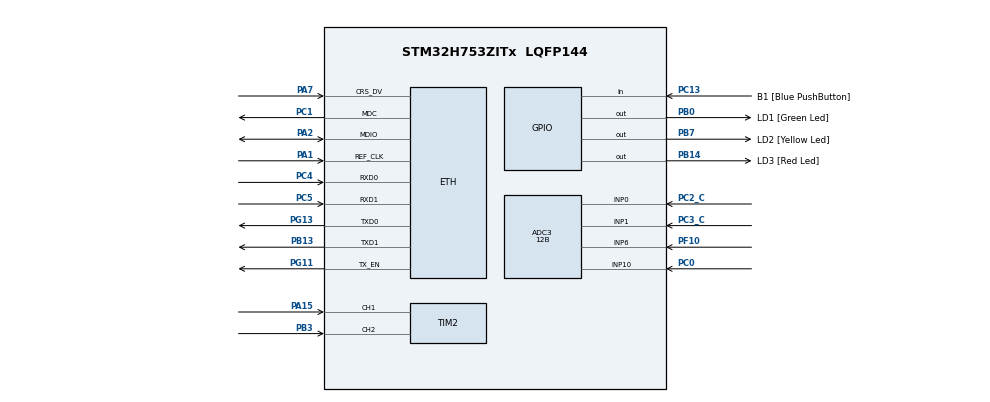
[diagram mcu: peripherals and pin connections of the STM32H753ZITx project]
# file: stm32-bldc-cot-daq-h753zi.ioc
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ADC3.Channel-1\#ChannelRegularConversion=ADC_CHANNEL_10
ADC3.Channel-2\#ChannelRegularConversion=ADC_CHANNEL_1
ADC3.Channel-3\#ChannelRegularConversion=ADC_CHANNEL_0
ADC3.Channel-4\#ChannelRegularConversion=ADC_CHANNEL_6
ADC3.ClockPrescaler=ADC_CLOCK_ASYNC_DIV2
ADC3.ConversionDataManagement=ADC_CONVERSIONDATA_DMA_CIRCULAR
ADC3.EOCSelection=ADC_EOC_SEQ_CONV
ADC3.ExternalTrigConv=ADC_EXTERNALTRIG_T3_TRGO
ADC3.NbrOfConversion=4
ADC3.NbrOfConversionFlag=1
ADC3.OffsetNumber-1\#ChannelRegularConversion=ADC_OFFSET_NONE
ADC3.OffsetNumber-2\#ChannelRegularConversion=ADC_OFFSET_NONE
ADC3.OffsetNumber-3\#ChannelRegularConversion=ADC_OFFSET_NONE
ADC3.OffsetNumber-4\#ChannelRegularConversion=ADC_OFFSET_NONE
ADC3.OffsetSignedSaturation-1\#ChannelRegularConversion=DISABLE
ADC3.OffsetSignedSaturation-2\#ChannelRegularConversion=DISABLE
ADC3.OffsetSignedSaturation-3\#ChannelRegularConversion=DISABLE
ADC3.OffsetSignedSaturation-4\#ChannelRegularConversion=DISABLE
ADC3.Rank-1\#ChannelRegularConversion=1
ADC3.Rank-2\#ChannelRegularConversion=2
ADC3.Rank-3\#ChannelRegularConversion=3
ADC3.Rank-4\#ChannelRegularConversion=4
ADC3.Resolution=ADC_RESOLUTION_12B
ADC3.SamplingTime-1\#ChannelRegularConversion=ADC_SAMPLETIME_16CYCLES_5
ADC3.SamplingTime-2\#ChannelRegularConversion=ADC_SAMPLETIME_16CYCLES_5
ADC3.SamplingTime-3\#ChannelRegularConversion=ADC_SAMPLETIME_16CYCLES_5
ADC3.SamplingTime-4\#ChannelRegularConversion=ADC_SAMPLETIME_16CYCLES_5
Bdma.ADC3.0.Direction=DMA_PERIPH_TO_MEMORY
Bdma.ADC3.0.EventEnable=DISABLE
Bdma.ADC3.0.Instance=BDMA_Channel0
Bdma.ADC3.0.MemDataAlignment=DMA_MDATAALIGN_HALFWORD
Bdma.ADC3.0.MemInc=DMA_MINC_ENABLE
Bdma.ADC3.0.Mode=DMA_CIRCULAR
Bdma.ADC3.0.PeriphDataAlignment=DMA_PDATAALIGN_HALFWORD
Bdma.ADC3.0.PeriphInc=DMA_PINC_DISABLE
Bdma.ADC3.0.Polarity=HAL_DMAMUX_REQ_GEN_RISING
Bdma.ADC3.0.Priority=DMA_PRIORITY_LOW
Bdma.ADC3.0.RequestNumber=1
Bdma.ADC3.0.SignalID=NONE
Bdma.ADC3.0.SyncEnable=DISABLE
Bdma.ADC3.0.SyncPolarity=HAL_DMAMUX_SYNC_NO_EVENT
Bdma.ADC3.0.SyncRequestNumber=1
Bdma.ADC3.0.SyncSignalID=NONE
Bdma.Request0=ADC3
Bdma.RequestsNb=1
CORTEX_M7.AccessPermission-Cortex_Memory_Protection_Unit_Region0_Settings=MPU_REGION_FULL_ACCESS
CORTEX_M7.BaseAddress-Cortex_Memory_Protection_Unit_Region0_Settings=0x30000000
CORTEX_M7.CPU_DCache=Enabled
CORTEX_M7.CPU_ICache=Enabled
CORTEX_M7.DisableExec-Cortex_Memory_Protection_Unit_Region0_Settings=MPU_INSTRUCTION_ACCESS_DISABLE
CORTEX_M7.Enable-Cortex_Memory_Protection_Unit_Region0_Settings=MPU_REGION_ENABLE
CORTEX_M7.IsShareable-Cortex_Memory_Protection_Unit_Region0_Settings=MPU_ACCESS_SHAREABLE
CORTEX_M7.MPU_Control=MPU_PRIVILEGED_DEFAULT
CORTEX_M7.Size-Cortex_Memory_Protection_Unit_Region0_Settings=MPU_REGION_SIZE_512KB
CORTEX_M7.TypeExtField-Cortex_Memory_Protection_Unit_Region0_Settings=MPU_TEX_LEVEL1
Dma.Request0=TIM2_CH1
Dma.Request1=TIM2_CH2
Dma.TIM2_CH1.0.Direction=DMA_PERIPH_TO_MEMORY
Dma.TIM2_CH1.0.EventEnable=DISABLE
Dma.TIM2_CH1.0.FIFOMode=DMA_FIFOMODE_DISABLE
Dma.TIM2_CH1.0.Instance=DMA1_Stream0
Dma.TIM2_CH1.0.MemDataAlignment=DMA_MDATAALIGN_WORD
Dma.TIM2_CH1.0.MemInc=DMA_MINC_ENABLE
Dma.TIM2_CH1.0.Mode=DMA_CIRCULAR
Dma.TIM2_CH1.0.PeriphDataAlignment=DMA_PDATAALIGN_WORD
Dma.TIM2_CH1.0.PeriphInc=DMA_PINC_DISABLE
Dma.TIM2_CH1.0.Polarity=HAL_DMAMUX_REQ_GEN_RISING
Dma.TIM2_CH1.0.Priority=DMA_PRIORITY_LOW
Dma.TIM2_CH1.0.RequestNumber=1
Dma.TIM2_CH1.0.SignalID=NONE
Dma.TIM2_CH1.0.SyncEnable=DISABLE
Dma.TIM2_CH1.0.SyncPolarity=HAL_DMAMUX_SYNC_NO_EVENT
Dma.TIM2_CH1.0.SyncRequestNumber=1
Dma.TIM2_CH1.0.SyncSignalID=NONE
Dma.TIM2_CH2.1.Direction=DMA_PERIPH_TO_MEMORY
Dma.TIM2_CH2.1.EventEnable=DISABLE
Dma.TIM2_CH2.1.FIFOMode=DMA_FIFOMODE_DISABLE
Dma.TIM2_CH2.1.Instance=DMA1_Stream1
Dma.TIM2_CH2.1.MemDataAlignment=DMA_MDATAALIGN_WORD
Dma.TIM2_CH2.1.MemInc=DMA_MINC_ENABLE
Dma.TIM2_CH2.1.Mode=DMA_CIRCULAR
Dma.TIM2_CH2.1.PeriphDataAlignment=DMA_PDATAALIGN_WORD
Dma.TIM2_CH2.1.PeriphInc=DMA_PINC_DISABLE
Dma.TIM2_CH2.1.Polarity=HAL_DMAMUX_REQ_GEN_RISING
Dma.TIM2_CH2.1.Priority=DMA_PRIORITY_LOW
Dma.TIM2_CH2.1.RequestNumber=1
Dma.TIM2_CH2.1.SignalID=NONE
Dma.TIM2_CH2.1.SyncEnable=DISABLE
Dma.TIM2_CH2.1.SyncPolarity=HAL_DMAMUX_SYNC_NO_EVENT
Dma.TIM2_CH2.1.SyncRequestNumber=1
Dma.TIM2_CH2.1.SyncSignalID=NONE
ETH.MediaInterface=HAL_ETH_RMII_MODE
LWIP.BSP.number=1
LWIP.IP_ADDRESS=192.168.008.130
LWIP.LWIP_DHCP=0
LWIP.LWIP_RAM_HEAP_POINTER=0x30020000
LWIP.MEM_SIZE=131040
LWIP.NETMASK_ADDRESS=255.255.255.000
LWIP.TCP_MSS=1426
LWIP.TCP_SND_BUF=4278
LWIP.Version=v2.1.2_Cube
LWIP0.BSP.STBoard=false
LWIP0.BSP.api=BSP_COMPONENT_DRIVER
LWIP0.BSP.component=LAN8742
LWIP0.BSP.instance=LAN8742
LWIP0.BSP.name=Driver_PHY
LWIP0.BSP.semaphore=S_LAN8742
LWIP0.BSP.solution=LAN8742
Mcu.Family=STM32H7
Mcu.Name=STM32H753ZITx
Mcu.Package=LQFP144
NVIC.BDMA_Channel0_IRQn=true\:0\:0\:false\:false\:true\:false\:true\:true
NVIC.DMA1_Stream0_IRQn=true\:0\:0\:false\:false\:true\:false\:true\:true
NVIC.DMA1_Stream1_IRQn=true\:0\:0\:false\:false\:true\:false\:true\:true
NVIC.ETH_IRQn=true\:0\:0\:false\:false\:true\:true\:true\:true
NVIC.PriorityGroup=NVIC_PRIORITYGROUP_4
NVIC.TIM3_IRQn=true\:0\:0\:false\:false\:true\:true\:true\:true
PA1.GPIO_Mode=GPIO_MODE_AF_PP
PA1.GPIO_PuPd=GPIO_NOPULL
PA1.GPIO_Speed=GPIO_SPEED_FREQ_VERY_HIGH
PA1.Mode=RMII
PA1.Signal=ETH_REF_CLK
PA15\ (JTDI).GPIO_PuPd=GPIO_PULLUP
PA15\ (JTDI).GPIO_Speed=GPIO_SPEED_FREQ_LOW
PA15\ (JTDI).Signal=S_TIM2_CH1_ETR
PA2.GPIO_Mode=GPIO_MODE_AF_PP
PA2.GPIO_PuPd=GPIO_NOPULL
PA2.GPIO_Speed=GPIO_SPEED_FREQ_VERY_HIGH
PA2.Mode=RMII
PA2.Signal=ETH_MDIO
PA7.GPIO_Mode=GPIO_MODE_AF_PP
PA7.GPIO_PuPd=GPIO_NOPULL
PA7.GPIO_Speed=GPIO_SPEED_FREQ_VERY_HIGH
PA7.Mode=RMII
PA7.Signal=ETH_CRS_DV
PB0.GPIO_Label=LD1 [Green Led]
PB0.Signal=GPIO_Output
PB13.GPIO_Mode=GPIO_MODE_AF_PP
PB13.GPIO_PuPd=GPIO_NOPULL
PB13.GPIO_Speed=GPIO_SPEED_FREQ_VERY_HIGH
PB13.Mode=RMII
PB13.Signal=ETH_TXD1
PB14.GPIO_Label=LD3 [Red Led]
PB14.Signal=GPIO_Output
PB3\ (JTDO/TRACESWO).GPIO_PuPd=GPIO_PULLUP
PB3\ (JTDO/TRACESWO).GPIO_Speed=GPIO_SPEED_FREQ_LOW
PB3\ (JTDO/TRACESWO).Signal=S_TIM2_CH2
PB7.GPIO_Label=LD2 [Yellow Led]
PB7.Signal=GPIO_Output
PC0.Signal=ADCx_INP10
PC1.GPIO_Mode=GPIO_MODE_AF_PP
PC1.GPIO_PuPd=GPIO_NOPULL
PC1.GPIO_Speed=GPIO_SPEED_FREQ_VERY_HIGH
PC1.Mode=RMII
PC1.Signal=ETH_MDC
PC13.GPIO_Label=B1 [Blue PushButton]
PC13.Signal=GPIO_Input
PC14-OSC32_IN\ (OSC32_IN).Signal=RCC_OSC32_IN
PC15-OSC32_OUT\ (OSC32_OUT).Signal=RCC_OSC32_OUT
PC2_C.Mode=IN0-Single-Ended
PC2_C.Signal=ADC3_INP0
PC3_C.Mode=IN1-Single-Ended
PC3_C.Signal=ADC3_INP1
PC4.GPIO_Mode=GPIO_MODE_AF_PP
PC4.GPIO_PuPd=GPIO_NOPULL
PC4.GPIO_Speed=GPIO_SPEED_FREQ_VERY_HIGH
PC4.Mode=RMII
PC4.Signal=ETH_RXD0
PC5.GPIO_Mode=GPIO_MODE_AF_PP
PC5.GPIO_PuPd=GPIO_NOPULL
PC5.GPIO_Speed=GPIO_SPEED_FREQ_VERY_HIGH
PC5.Mode=RMII
PC5.Signal=ETH_RXD1
PD8.GPIO_Label=STLINK_RX
PD8.Signal=USART3_TX
PD9.GPIO_Label=STLINK_TX
PD9.Signal=USART3_RX
PF10.Mode=IN6-Single-Ended
PF10.Signal=ADC3_INP6
PG11.GPIO_Mode=GPIO_MODE_AF_PP
PG11.GPIO_PuPd=GPIO_NOPULL
PG11.GPIO_Speed=GPIO_SPEED_FREQ_VERY_HIGH
PG11.Mode=RMII
PG11.Signal=ETH_TX_EN
PG13.GPIO_Mode=GPIO_MODE_AF_PP
PG13.GPIO_PuPd=GPIO_NOPULL
PG13.GPIO_Speed=GPIO_SPEED_FREQ_VERY_HIGH
PG13.Mode=RMII
PG13.Signal=ETH_TXD0
PH0-OSC_IN\ (PH0).Signal=RCC_OSC_IN
PH1-OSC_OUT\ (PH1).Signal=RCC_OSC_OUT
ProjectManager.HeapSize=0x200
ProjectManager.StackSize=0x400
ProjectManager.TargetToolchain=STM32CubeIDE
RCC.ADCFreq_Value=50000000
RCC.APB1Freq_Value=100000000
RCC.APB2Freq_Value=100000000
RCC.APB3Freq_Value=100000000
RCC.APB4Freq_Value=100000000
RCC.CortexFreq_Value=400000000
RCC.D1PPRE=RCC_APB3_DIV2
RCC.D2PPRE1=RCC_APB1_DIV2
RCC.D2PPRE2=RCC_APB2_DIV2
RCC.D3PPRE=RCC_APB4_DIV2
RCC.DIVM1=4
RCC.DIVN1=50
RCC.DIVN2=200
RCC.DIVP2=8
RCC.DIVQ1=4
RCC.HCLKFreq_Value=200000000
RCC.HPRE=RCC_HCLK_DIV2
RCC.HSE_VALUE=8000000
RCC.PLL2FRACN=0
RCC.PLL3FRACN=0
RCC.PLLFRACN=0
RCC.PWR_Regulator_Voltage_Scale=PWR_REGULATOR_VOLTAGE_SCALE0
RCC.SYSCLKFreq_VALUE=400000000
RCC.SYSCLKSource=RCC_SYSCLKSOURCE_PLLCLK
RCC.USBCLockSelection=RCC_USBCLKSOURCE_HSI48
RCC.USBFreq_Value=48000000
SH.ADCx_INP10.0=ADC3_INP10,IN10-Single-Ended
SH.S_TIM2_CH1_ETR.0=TIM2_CH1,Input_Capture1_from_TI1
SH.S_TIM2_CH2.0=TIM2_CH2,Input_Capture2_from_TI2
TIM2.Channel-Input_Capture1_from_TI1=TIM_CHANNEL_1
TIM2.Channel-Input_Capture2_from_TI2=TIM_CHANNEL_2
TIM2.ICFilter_CH1=7
TIM2.ICFilter_CH2=11
TIM2.TIM_MasterOutputTrigger=TIM_TRGO_OC1
TIM2.TIM_MasterSlaveMode=TIM_MASTERSLAVEMODE_DISABLE
TIM3.Period=2
TIM3.TIM_MasterOutputTrigger=TIM_TRGO_UPDATE
VP_CRC_VS_CRC.Mode=CRC_Activate
VP_LWIP_VS_Enabled.Mode=Enabled
VP_MEMORYMAP_VS_MEMORYMAP.Mode=CurAppReg
VP_TIM3_VS_ClockSourceITR.Mode=TriggerSource_ITR1
VP_TIM3_VS_ControllerModeClock.Mode=Clock Mode
board=NUCLEO-H753ZI

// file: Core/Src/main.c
/* USER CODE BEGIN Header */
/**
  ******************************************************************************
  * @file           : main.c
  * @brief          : Main program body
  ******************************************************************************
  * @attention
  *
  * Copyright (c) 2026 STMicroelectronics.
  * All rights reserved.
  *
  * This software is licensed under terms that can be found in the LICENSE file
  * in the root directory of this software component.
  * If no LICENSE file comes with this software, it is provided AS-IS.
  *
  ******************************************************************************
  */
/* USER CODE END Header */
#include "main.h"
#include "adc.h"
#include "bdma.h"
#include "crc.h"
#include "dma.h"
#include "lwip.h"
#include "tim.h"
#include "gpio.h"

/* USER CODE BEGIN Includes */
#include "application.h"
/* USER CODE END Includes */

void SystemClock_Config(void);
static void MPU_Config(void);

int main(void)
{

  /* MPU Configuration--------------------------------------------------------*/
  MPU_Config();

  /* Enable the CPU Cache */

  /* Enable I-Cache---------------------------------------------------------*/
  SCB_EnableICache();

  /* Enable D-Cache---------------------------------------------------------*/
  SCB_EnableDCache();

  /* MCU Configuration--------------------------------------------------------*/

  /* Reset of all peripherals, Initializes the Flash interface and the Systick. */
  HAL_Init();

  /* Configure the system clock */
  SystemClock_Config();

  /* Initialize all configured peripherals */
  MX_GPIO_Init();
  MX_DMA_Init();
  MX_BDMA_Init();
  MX_TIM2_Init();
  MX_LWIP_Init();
  MX_CRC_Init();
  MX_ADC3_Init();
  MX_TIM3_Init();
  /* USER CODE BEGIN 2 */
  HAL_ADCEx_Calibration_Start(&hadc3, ADC_CALIB_OFFSET_LINEARITY, ADC_SINGLE_ENDED);
  HAL_ADCEx_Calibration_Start(&hadc3, ADC_CALIB_OFFSET, ADC_SINGLE_ENDED);
  application_entry();
  /* USER CODE END 2 */

  /* Infinite loop */
  while (1)
  {

  }
}

void SystemClock_Config(void)
{
  RCC_OscInitTypeDef RCC_OscInitStruct = {0};
  RCC_ClkInitTypeDef RCC_ClkInitStruct = {0};

  /** Supply configuration update enable
  */
  HAL_PWREx_ConfigSupply(PWR_LDO_SUPPLY);

  /** Configure the main internal regulator output voltage
  */
  __HAL_PWR_VOLTAGESCALING_CONFIG(PWR_REGULATOR_VOLTAGE_SCALE0);

  while(!__HAL_PWR_GET_FLAG(PWR_FLAG_VOSRDY)) {}

  /** Initializes the RCC Oscillators according to the specified parameters
  * in the RCC_OscInitTypeDef structure.
  */
  RCC_OscInitStruct.OscillatorType = RCC_OSCILLATORTYPE_HSI;
  RCC_OscInitStruct.HSIState = RCC_HSI_DIV1;
  RCC_OscInitStruct.HSICalibrationValue = RCC_HSICALIBRATION_DEFAULT;
  RCC_OscInitStruct.PLL.PLLState = RCC_PLL_ON;
  RCC_OscInitStruct.PLL.PLLSource = RCC_PLLSOURCE_HSI;
  RCC_OscInitStruct.PLL.PLLM = 4;
  RCC_OscInitStruct.PLL.PLLN = 50;
  RCC_OscInitStruct.PLL.PLLP = 2;
  RCC_OscInitStruct.PLL.PLLQ = 4;
  RCC_OscInitStruct.PLL.PLLR = 2;
  RCC_OscInitStruct.PLL.PLLRGE = RCC_PLL1VCIRANGE_3;
  RCC_OscInitStruct.PLL.PLLVCOSEL = RCC_PLL1VCOWIDE;
  RCC_OscInitStruct.PLL.PLLFRACN = 0;
  if (HAL_RCC_OscConfig(&RCC_OscInitStruct) != HAL_OK)
  {
    Error_Handler();
  }

  /** Initializes the CPU, AHB and APB buses clocks
  */
  RCC_ClkInitStruct.ClockType = RCC_CLOCKTYPE_HCLK|RCC_CLOCKTYPE_SYSCLK
                              |RCC_CLOCKTYPE_PCLK1|RCC_CLOCKTYPE_PCLK2
                              |RCC_CLOCKTYPE_D3PCLK1|RCC_CLOCKTYPE_D1PCLK1;
  RCC_ClkInitStruct.SYSCLKSource = RCC_SYSCLKSOURCE_PLLCLK;
  RCC_ClkInitStruct.SYSCLKDivider = RCC_SYSCLK_DIV1;
  RCC_ClkInitStruct.AHBCLKDivider = RCC_HCLK_DIV2;
  RCC_ClkInitStruct.APB3CLKDivider = RCC_APB3_DIV2;
  RCC_ClkInitStruct.APB1CLKDivider = RCC_APB1_DIV2;
  RCC_ClkInitStruct.APB2CLKDivider = RCC_APB2_DIV2;
  RCC_ClkInitStruct.APB4CLKDivider = RCC_APB4_DIV2;

  if (HAL_RCC_ClockConfig(&RCC_ClkInitStruct, FLASH_LATENCY_2) != HAL_OK)
  {
    Error_Handler();
  }
}

 /* MPU Configuration */

void MPU_Config(void)
{
  MPU_Region_InitTypeDef MPU_InitStruct = {0};

  /* Disables the MPU */
  HAL_MPU_Disable();

  /** Initializes and configures the Region and the memory to be protected
  */
  MPU_InitStruct.Enable = MPU_REGION_ENABLE;
  MPU_InitStruct.Number = MPU_REGION_NUMBER0;
  MPU_InitStruct.BaseAddress = 0x30000000;
  MPU_InitStruct.Size = MPU_REGION_SIZE_512KB;
  MPU_InitStruct.SubRegionDisable = 0x0;
  MPU_InitStruct.TypeExtField = MPU_TEX_LEVEL1;
  MPU_InitStruct.AccessPermission = MPU_REGION_FULL_ACCESS;
  MPU_InitStruct.DisableExec = MPU_INSTRUCTION_ACCESS_DISABLE;
  MPU_InitStruct.IsShareable = MPU_ACCESS_SHAREABLE;
  MPU_InitStruct.IsCacheable = MPU_ACCESS_NOT_CACHEABLE;
  MPU_InitStruct.IsBufferable = MPU_ACCESS_NOT_BUFFERABLE;

  HAL_MPU_ConfigRegion(&MPU_InitStruct);
  /* Enables the MPU */
  HAL_MPU_Enable(MPU_PRIVILEGED_DEFAULT);

}

void Error_Handler(void)
{
  __disable_irq();
  while (1)
  {
  }
}
